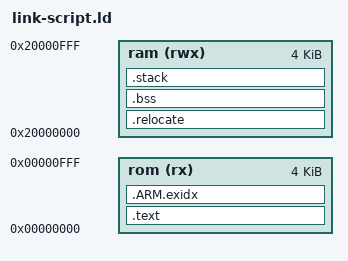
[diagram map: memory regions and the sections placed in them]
/**
 * \file
 *
 * ORIGINALLY Linker script for running in internal FLASH on the SAMD21E15A 
 *
 * BUT NOW: a specialized bootloader linker script: 
 *  - limits itself to first 4k of device.
 *  - assumes only a small amount of ram is available.
 *  - tries to work on all devices in the family
 *
 * Copyright (c) 2014 Atmel Corporation. All rights reserved.
 *
 * \asf_license_start
 *
 * \page License
 *
 * Redistribution and use in source and binary forms, with or without
 * modification, are permitted provided that the following conditions are met:
 *
 * 1. Redistributions of source code must retain the above copyright notice,
 *    this list of conditions and the following disclaimer.
 *
 * 2. Redistributions in binary form must reproduce the above copyright notice,
 *    this list of conditions and the following disclaimer in the documentation
 *    and/or other materials provided with the distribution.
 *
 * 3. The name of Atmel may not be used to endorse or promote products derived
 *    from this software without specific prior written permission.
 *
 * 4. This software may only be redistributed and used in connection with an
 *    Atmel microcontroller product.
 *
 * THIS SOFTWARE IS PROVIDED BY ATMEL "AS IS" AND ANY EXPRESS OR IMPLIED
 * WARRANTIES, INCLUDING, BUT NOT LIMITED TO, THE IMPLIED WARRANTIES OF
 * MERCHANTABILITY, FITNESS FOR A PARTICULAR PURPOSE AND NON-INFRINGEMENT ARE
 * EXPRESSLY AND SPECIFICALLY DISCLAIMED. IN NO EVENT SHALL ATMEL BE LIABLE FOR
 * ANY DIRECT, INDIRECT, INCIDENTAL, SPECIAL, EXEMPLARY, OR CONSEQUENTIAL
 * DAMAGES (INCLUDING, BUT NOT LIMITED TO, PROCUREMENT OF SUBSTITUTE GOODS
 * OR SERVICES; LOSS OF USE, DATA, OR PROFITS; OR BUSINESS INTERRUPTION)
 * HOWEVER CAUSED AND ON ANY THEORY OF LIABILITY, WHETHER IN CONTRACT,
 * STRICT LIABILITY, OR TORT (INCLUDING NEGLIGENCE OR OTHERWISE) ARISING IN
 * ANY WAY OUT OF THE USE OF THIS SOFTWARE, EVEN IF ADVISED OF THE
 * POSSIBILITY OF SUCH DAMAGE.
 *
 * \asf_license_stop
 *
 */


OUTPUT_FORMAT("elf32-littlearm", "elf32-littlearm", "elf32-littlearm")
OUTPUT_ARCH(arm)
SEARCH_DIR(.)

/* Memory Spaces Definitions */
MEMORY
{
  rom    (rx)  : ORIGIN = 0x00000000, LENGTH = 0x00001000
  ram    (rwx) : ORIGIN = 0x20000000, LENGTH = 0x00001000
}

/* The stack size used by the bootloader.

	When the real app runs the SP will be changed to suit it's needs, so this
	value here is set to match the smallest part, so should never need to change here.
*/
STACK_SIZE = DEFINED(STACK_SIZE) ? STACK_SIZE : DEFINED(__stack_size__) ? __stack_size__ : 0x400;

/* Section Definitions */
SECTIONS
{
    .text :
    {
        . = ALIGN(4);
        _sfixed = .;
        KEEP(*(.vectors .vectors.*))
        KEEP(*(.copyright))
        *(.text .text.* .gnu.linkonce.t.*)
        *(.glue_7t) *(.glue_7)
        *(.rodata .rodata* .gnu.linkonce.r.*)
        *(.ARM.extab* .gnu.linkonce.armextab.*)

        /* Support C constructors, and C destructors in both user code
           and the C library. This also provides support for C++ code. */
        . = ALIGN(4);
        KEEP(*(.init))
        . = ALIGN(4);
        __preinit_array_start = .;
        KEEP (*(.preinit_array))
        __preinit_array_end = .;

        . = ALIGN(4);
        __init_array_start = .;
        KEEP (*(SORT(.init_array.*)))
        KEEP (*(.init_array))
        __init_array_end = .;

        . = ALIGN(4);
        KEEP (*crtbegin.o(.ctors))
        KEEP (*(EXCLUDE_FILE (*crtend.o) .ctors))
        KEEP (*(SORT(.ctors.*)))
        KEEP (*crtend.o(.ctors))

        . = ALIGN(4);
        KEEP(*(.fini))

        . = ALIGN(4);
        __fini_array_start = .;
        KEEP (*(.fini_array))
        KEEP (*(SORT(.fini_array.*)))
        __fini_array_end = .;

        KEEP (*crtbegin.o(.dtors))
        KEEP (*(EXCLUDE_FILE (*crtend.o) .dtors))
        KEEP (*(SORT(.dtors.*)))
        KEEP (*crtend.o(.dtors))

        . = ALIGN(4);
        _efixed = .;            /* End of text section */
    } > rom

    /* .ARM.exidx is sorted, so has to go in its own output section.  */
    PROVIDE_HIDDEN (__exidx_start = .);
    .ARM.exidx :
    {
      *(.ARM.exidx* .gnu.linkonce.armexidx.*)
    } > rom
    PROVIDE_HIDDEN (__exidx_end = .);

    . = ALIGN(4);
    _etext = .;

    .relocate : AT (_etext)
    {
        . = ALIGN(4);
        _srelocate = .;
        *(.ramfunc .ramfunc.*);
        *(.data .data.*);
        . = ALIGN(4);
        _erelocate = .;
    } > ram

	/* if you initialize a global var to some non-zero value, then that data ends up
		in .relocate as read-only data and used briefly at startup (when copied to RAM).
		We don't want to support that, so we're checking here that hasn't happened.
	*/
	ASSERT(_srelocate == _erelocate, 
				"DAFU: Sorry, no initialized data support! Set to zero or remove.")

    /* .bss section which is used for uninitialized data */
    .bss (NOLOAD) :
    {
        . = ALIGN(4);
        _sbss = . ;
        _szero = .;
        *(.bss .bss.*)
        *(COMMON)
        . = ALIGN(4);
        _ebss = . ;
        _ezero = .;
    } > ram

    /* stack section */
    .stack (NOLOAD):
    {
        . = ALIGN(8);
        _sstack = .;
        . = . + STACK_SIZE;
        . = ALIGN(8);
        _estack = .;
    } > ram

    . = ALIGN(4);
    _end = . ;
}
